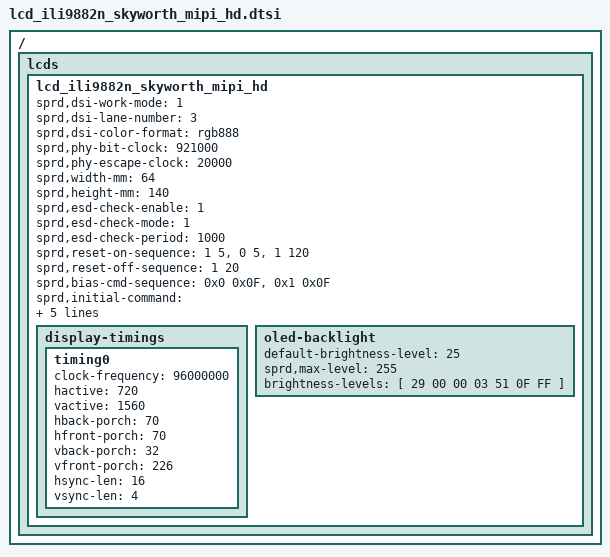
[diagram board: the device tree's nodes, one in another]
/ { lcds {
	lcd_ili9882n_skyworth_mipi_hd: lcd_ili9882n_skyworth_mipi_hd {

		sprd,dsi-work-mode = <1>;
		sprd,dsi-lane-number = <3>;
		sprd,dsi-color-format = "rgb888";

		sprd,phy-bit-clock = <921000>;
		sprd,phy-escape-clock = <20000>;

		sprd,width-mm = <64>;
		sprd,height-mm = <140>;

		sprd,esd-check-enable = <1>;
		sprd,esd-check-mode = <1>;
		sprd,esd-check-period = <1000>;

		sprd,reset-on-sequence = <1 5>, <0 5>, <1 120>;
		sprd,reset-off-sequence = <1 20>;
		sprd,bias-cmd-sequence =  <0x0 0x0F>, <0x1 0x0F>;

		sprd,initial-command = [
			39 00 00 04 FF 98 82 00
			39 00 00 03 68 04 00
		        39 00 00 03 51 00 00
			23 00 00 02 35 00
		        23 00 00 02 53 2c
		        23 00 00 02 55 01
		        13 78 00 01 11
		        39 00 00 04 FF 98 82 03
			23 00 00 02 80 06
			23 00 00 02 81 06
			23 00 00 02 82 06
		        23 00 00 02 83 20
			23 00 00 02 84 00
		        39 00 00 04 FF 98 82 06
        		23 00 00 02 D9 10
			23 00 00 02 06 A4
			23 00 00 02 80 00
        		39 00 00 04 FF 98 82 00
		        13 14 00 01 29
			];
		sprd,sleep-in-command = [
			13 0A 00 01 28
			13 78 00 01 10
			];
		sprd,sleep-out-command = [
			13 78 00 01 11
			13 64 00 01 29
			];

		display-timings {
			timing0 {
				clock-frequency = <96000000>;
				hactive = <720>;
				vactive = <1560>;
				hback-porch = <70>;
				hfront-porch = <70>;
				vback-porch = <32>;
				vfront-porch = <226>;
				hsync-len = <16>;
				vsync-len = <4>;
			};
		};

oled-backlight{
	default-brightness-level = <25>;
	sprd,max-level = <255>;
	brightness-levels = [
		29 00 00 03 51 0F FF
	];
};
};

};};


